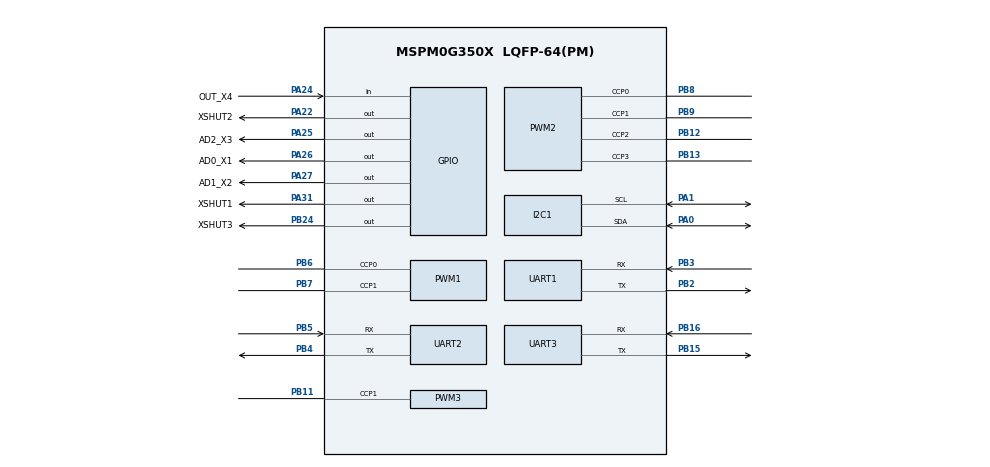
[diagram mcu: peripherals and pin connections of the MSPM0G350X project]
/**
 * @cliArgs --device "MSPM0G350X" --part "Default" --package "LQFP-64(PM)" --product "mspm0_sdk@2.02.00.05"
 * @versions {"tool":"1.21.1+3772"}
 */

/**
 * Import the modules used in this configuration.
 */
const ADC12   = scripting.addModule("/ti/driverlib/ADC12", {}, false);
const ADC121  = ADC12.addInstance();
const GPIO    = scripting.addModule("/ti/driverlib/GPIO", {}, false);
const GPIO1   = GPIO.addInstance();
const GPIO2   = GPIO.addInstance();
const GPIO3   = GPIO.addInstance();
const GPIO4   = GPIO.addInstance();
const GPIO5   = GPIO.addInstance();
const I2C     = scripting.addModule("/ti/driverlib/I2C", {}, false);
const I2C1    = I2C.addInstance();
const PWM     = scripting.addModule("/ti/driverlib/PWM", {}, false);
const PWM1    = PWM.addInstance();
const PWM2    = PWM.addInstance();
const PWM3    = PWM.addInstance();
const SYSCTL  = scripting.addModule("/ti/driverlib/SYSCTL");
const SYSTICK = scripting.addModule("/ti/driverlib/SYSTICK");
const TIMER   = scripting.addModule("/ti/driverlib/TIMER", {}, false);
const TIMER1  = TIMER.addInstance();
const UART    = scripting.addModule("/ti/driverlib/UART", {}, false);
const UART1   = UART.addInstance();
const UART2   = UART.addInstance();
const UART3   = UART.addInstance();
const UART4   = UART.addInstance();

/**
 * Write custom configuration values to the imported modules.
 */
const divider6       = system.clockTree["PLL_CLK2X_DIV"];
divider6.divideValue = 4;

const divider7       = system.clockTree["PLL_PDIV"];
divider7.divideValue = 2;

const divider9       = system.clockTree["UDIV"];
divider9.divideValue = 2;

const gate7  = system.clockTree["MFCLKGATE"];
gate7.enable = true;

const multiplier2         = system.clockTree["PLL_QDIV"];
multiplier2.multiplyValue = 10;

const mux8       = system.clockTree["HSCLKMUX"];
mux8.inputSelect = "HSCLKMUX_SYSPLL2X";

ADC121.$name                             = "ADC_BAT";
ADC121.enabledInterrupts                 = ["DL_ADC12_INTERRUPT_MEM0_RESULT_LOADED"];
ADC121.adcMem0trig                       = "DL_ADC12_TRIGGER_MODE_TRIGGER_NEXT";
ADC121.sampClkSrc                        = "DL_ADC12_CLOCK_ULPCLK";
ADC121.sampClkDiv                        = "DL_ADC12_CLOCK_DIVIDE_8";
ADC121.powerDownMode                     = "DL_ADC12_POWER_DOWN_MODE_MANUAL";
ADC121.sampleTime1                       = "0.25ms";
ADC121.sampleTime0                       = "0.25ms";
ADC121.peripheral.$assign                = "ADC1";
ADC121.peripheral.adcPin0.$assign        = "PA15";
ADC121.adcPin0Config.hideOutputInversion = scripting.forceWrite(false);
ADC121.adcPin0Config.$name               = "ti_driverlib_gpio_GPIOPinGeneric14";

const Board = scripting.addModule("/ti/driverlib/Board", {}, false);

GPIO1.$name                         = "XSHUT";
GPIO1.associatedPins.create(3);
GPIO1.associatedPins[0].$name       = "XSHUT1";
GPIO1.associatedPins[0].pin.$assign = "PA31";
GPIO1.associatedPins[1].$name       = "XSHUT2";
GPIO1.associatedPins[1].pin.$assign = "PA22";
GPIO1.associatedPins[2].$name       = "XSHUT3";
GPIO1.associatedPins[2].pin.$assign = "PB24";

GPIO2.$name                         = "LINE_FOLLOW";
GPIO2.associatedPins.create(4);
GPIO2.associatedPins[0].$name       = "AD0_X1";
GPIO2.associatedPins[0].pin.$assign = "PA26";
GPIO2.associatedPins[1].$name       = "AD1_X2";
GPIO2.associatedPins[1].pin.$assign = "PA27";
GPIO2.associatedPins[2].$name       = "AD2_X3";
GPIO2.associatedPins[2].pin.$assign = "PA25";
GPIO2.associatedPins[3].$name       = "OUT_X4";
GPIO2.associatedPins[3].direction   = "INPUT";
GPIO2.associatedPins[3].pin.$assign = "PA24";

GPIO3.$name                              = "KEY";
GPIO3.associatedPins.create(4);
GPIO3.associatedPins[0].$name            = "KEY2";
GPIO3.associatedPins[0].direction        = "INPUT";
GPIO3.associatedPins[0].assignedPort     = "PORTA";
GPIO3.associatedPins[0].assignedPin      = "8";
GPIO3.associatedPins[0].internalResistor = "PULL_UP";
GPIO3.associatedPins[1].$name            = "KEY1";
GPIO3.associatedPins[1].direction        = "INPUT";
GPIO3.associatedPins[1].assignedPort     = "PORTA";
GPIO3.associatedPins[1].assignedPin      = "28";
GPIO3.associatedPins[1].internalResistor = "PULL_UP";
GPIO3.associatedPins[2].$name            = "KEY3";
GPIO3.associatedPins[2].direction        = "INPUT";
GPIO3.associatedPins[2].assignedPort     = "PORTA";
GPIO3.associatedPins[2].assignedPin      = "9";
GPIO3.associatedPins[2].internalResistor = "PULL_UP";
GPIO3.associatedPins[3].$name            = "STOP";
GPIO3.associatedPins[3].direction        = "INPUT";
GPIO3.associatedPins[3].assignedPort     = "PORTB";
GPIO3.associatedPins[3].internalResistor = "PULL_UP";
GPIO3.associatedPins[3].assignedPin      = "1";

GPIO4.$name                          = "LED";
GPIO4.associatedPins.create(3);
GPIO4.associatedPins[0].$name        = "LED_0";
GPIO4.associatedPins[0].assignedPort = "PORTA";
GPIO4.associatedPins[0].assignedPin  = "30";
GPIO4.associatedPins[1].$name        = "LED_1";
GPIO4.associatedPins[1].assignedPort = "PORTB";
GPIO4.associatedPins[1].assignedPin  = "0";
GPIO4.associatedPins[2].$name        = "LED_2";
GPIO4.associatedPins[2].assignedPort = "PORTB";
GPIO4.associatedPins[2].assignedPin  = "22";

GPIO5.$name                                 = "ENCODER";
GPIO5.associatedPins.create(4);
GPIO5.associatedPins[0].$name               = "E1A";
GPIO5.associatedPins[0].direction           = "INPUT";
GPIO5.associatedPins[0].interruptEn         = true;
GPIO5.associatedPins[0].polarity            = "RISE_FALL";
GPIO5.associatedPins[0].assignedPort        = "PORTA";
GPIO5.associatedPins[0].assignedPin         = "12";
GPIO5.associatedPins[0].inputFilter         = "3_CYCLES";
GPIO5.associatedPins[1].$name               = "E1B";
GPIO5.associatedPins[1].direction           = "INPUT";
GPIO5.associatedPins[1].assignedPort        = "PORTA";
GPIO5.associatedPins[1].assignedPin         = "13";
GPIO5.associatedPins[1].interruptEn         = true;
GPIO5.associatedPins[1].polarity            = "RISE";
GPIO5.associatedPins[1].inputFilter         = "3_CYCLES";
GPIO5.associatedPins[2].$name               = "E2A";
GPIO5.associatedPins[2].direction           = "INPUT";
GPIO5.associatedPins[2].assignedPort        = "PORTB";
GPIO5.associatedPins[2].assignedPin         = "23";
GPIO5.associatedPins[2].interruptEn         = true;
GPIO5.associatedPins[2].polarity            = "RISE_FALL";
GPIO5.associatedPins[2].inputFilter         = "8_CYCLES";
GPIO5.associatedPins[3].$name               = "E2B";
GPIO5.associatedPins[3].direction           = "INPUT";
GPIO5.associatedPins[3].assignedPin         = "27";
GPIO5.associatedPins[3].interruptEn         = true;
GPIO5.associatedPins[3].polarity            = "RISE";
GPIO5.associatedPins[3].assignedPort        = "PORTB";
GPIO5.associatedPins[3].assignedPortSegment = "Upper";
GPIO5.associatedPins[3].inputFilter         = "8_CYCLES";

I2C1.$name                             = "I2C_VL53L0X";
I2C1.basicEnableController             = true;
I2C1.advDigitalGlitchFilter            = "CLOCKS_1";
I2C1.enableDMAEvent1                   = false;
I2C1.enableDMAEvent2                   = false;
I2C1.basicTargetSecAddressEnable       = true;
I2C1.peripheral.$assign                = "I2C0";
I2C1.peripheral.sdaPin.$assign         = "PA0";
I2C1.peripheral.sclPin.$assign         = "PA1";
I2C1.sdaPinConfig.hideOutputInversion  = scripting.forceWrite(false);
I2C1.sdaPinConfig.onlyInternalResistor = scripting.forceWrite(false);
I2C1.sdaPinConfig.passedPeripheralType = scripting.forceWrite("Digital");
I2C1.sdaPinConfig.$name                = "ti_driverlib_gpio_GPIOPinGeneric8";
I2C1.sdaPinConfig.enableConfig         = true;
I2C1.sclPinConfig.hideOutputInversion  = scripting.forceWrite(false);
I2C1.sclPinConfig.onlyInternalResistor = scripting.forceWrite(false);
I2C1.sclPinConfig.passedPeripheralType = scripting.forceWrite("Digital");
I2C1.sclPinConfig.$name                = "ti_driverlib_gpio_GPIOPinGeneric9";
I2C1.sclPinConfig.enableConfig         = true;

PWM1.clockPrescale                      = 160;
PWM1.timerCount                         = 10000;
PWM1.$name                              = "SERVO";
PWM1.pwmMode                            = "EDGE_ALIGN_UP";
PWM1.peripheral.$assign                 = "TIMG6";
PWM1.peripheral.ccp0Pin.$assign         = "PB6";
PWM1.peripheral.ccp1Pin.$assign         = "PB7";
PWM1.PWM_CHANNEL_0.$name                = "ti_driverlib_pwm_PWMTimerCC2";
PWM1.PWM_CHANNEL_1.$name                = "ti_driverlib_pwm_PWMTimerCC3";
PWM1.ccp0PinConfig.direction            = scripting.forceWrite("OUTPUT");
PWM1.ccp0PinConfig.hideOutputInversion  = scripting.forceWrite(false);
PWM1.ccp0PinConfig.onlyInternalResistor = scripting.forceWrite(false);
PWM1.ccp0PinConfig.passedPeripheralType = scripting.forceWrite("Digital");
PWM1.ccp0PinConfig.$name                = "ti_driverlib_gpio_GPIOPinGeneric12";
PWM1.ccp1PinConfig.direction            = scripting.forceWrite("OUTPUT");
PWM1.ccp1PinConfig.hideOutputInversion  = scripting.forceWrite(false);
PWM1.ccp1PinConfig.onlyInternalResistor = scripting.forceWrite(false);
PWM1.ccp1PinConfig.passedPeripheralType = scripting.forceWrite("Digital");
PWM1.ccp1PinConfig.$name                = "ti_driverlib_gpio_GPIOPinGeneric13";

PWM2.$name                              = "MOTOR";
PWM2.ccIndex                            = [0,1,2,3];
PWM2.timerCount                         = 8000;
PWM2.pwmMode                            = "EDGE_ALIGN_UP";
PWM2.peripheral.$assign                 = "TIMA0";
PWM2.peripheral.ccp0Pin.$assign         = "PB8";
PWM2.peripheral.ccp1Pin.$assign         = "PB9";
PWM2.peripheral.ccp2Pin.$assign         = "PB12";
PWM2.peripheral.ccp3Pin.$assign         = "PB13";
PWM2.PWM_CHANNEL_0.$name                = "ti_driverlib_pwm_PWMTimerCC0";
PWM2.PWM_CHANNEL_1.$name                = "ti_driverlib_pwm_PWMTimerCC1";
PWM2.ccp0PinConfig.direction            = scripting.forceWrite("OUTPUT");
PWM2.ccp0PinConfig.hideOutputInversion  = scripting.forceWrite(false);
PWM2.ccp0PinConfig.onlyInternalResistor = scripting.forceWrite(false);
PWM2.ccp0PinConfig.passedPeripheralType = scripting.forceWrite("Digital");
PWM2.ccp0PinConfig.$name                = "ti_driverlib_gpio_GPIOPinGeneric10";
PWM2.ccp1PinConfig.direction            = scripting.forceWrite("OUTPUT");
PWM2.ccp1PinConfig.hideOutputInversion  = scripting.forceWrite(false);
PWM2.ccp1PinConfig.onlyInternalResistor = scripting.forceWrite(false);
PWM2.ccp1PinConfig.passedPeripheralType = scripting.forceWrite("Digital");
PWM2.ccp1PinConfig.$name                = "ti_driverlib_gpio_GPIOPinGeneric11";
PWM2.PWM_CHANNEL_2.$name                = "ti_driverlib_pwm_PWMTimerCC4";
PWM2.PWM_CHANNEL_3.$name                = "ti_driverlib_pwm_PWMTimerCC5";
PWM2.ccp2PinConfig.$name                = "ti_driverlib_gpio_GPIOPinGeneric15";
PWM2.ccp3PinConfig.$name                = "ti_driverlib_gpio_GPIOPinGeneric16";

PWM3.timerCount                         = 10000;
PWM3.clockPrescale                      = 80;
PWM3.$name                              = "SERVO3";
PWM3.ccIndex                            = [1];
PWM3.pwmMode                            = "EDGE_ALIGN_UP";
PWM3.peripheral.ccp1Pin.$assign         = "PB11";
PWM3.ccp1PinConfig.$name                = "ti_driverlib_gpio_GPIOPinGeneric18";
PWM3.ccp1PinConfig.direction            = scripting.forceWrite("OUTPUT");
PWM3.ccp1PinConfig.hideOutputInversion  = scripting.forceWrite(false);
PWM3.ccp1PinConfig.onlyInternalResistor = scripting.forceWrite(false);
PWM3.ccp1PinConfig.passedPeripheralType = scripting.forceWrite("Digital");
PWM3.PWM_CHANNEL_1.$name                = "ti_driverlib_pwm_PWMTimerCC6";

SYSCTL.forceDefaultClkConfig = true;
SYSCTL.clockTreeEn           = true;

SYSTICK.periodEnable      = true;
SYSTICK.interruptEnable   = true;
SYSTICK.systickEnable     = true;
SYSTICK.period            = 80000;
SYSTICK.interruptPriority = "0";

TIMER1.$name              = "TIMER_0";
TIMER1.timerClkSrc        = "MFCLK";
TIMER1.interruptPriority  = "2";
TIMER1.timerPeriod        = "1ms";
TIMER1.interrupts         = ["ZERO"];
TIMER1.timerMode          = "PERIODIC";
TIMER1.peripheral.$assign = "TIMA1";

UART1.$name                            = "MSPMotor";
UART1.targetBaudRate                   = 115200;
UART1.uartClkSrc                       = "MFCLK";
UART1.interruptPriority                = "1";
UART1.enabledInterrupts                = ["RX"];
UART1.peripheral.$assign               = "UART3";
UART1.peripheral.rxPin.$assign         = "PB3";
UART1.peripheral.txPin.$assign         = "PB2";
UART1.txPinConfig.direction            = scripting.forceWrite("OUTPUT");
UART1.txPinConfig.hideOutputInversion  = scripting.forceWrite(false);
UART1.txPinConfig.onlyInternalResistor = scripting.forceWrite(false);
UART1.txPinConfig.passedPeripheralType = scripting.forceWrite("Digital");
UART1.txPinConfig.$name                = "ti_driverlib_gpio_GPIOPinGeneric2";
UART1.rxPinConfig.hideOutputInversion  = scripting.forceWrite(false);
UART1.rxPinConfig.onlyInternalResistor = scripting.forceWrite(false);
UART1.rxPinConfig.passedPeripheralType = scripting.forceWrite("Digital");
UART1.rxPinConfig.$name                = "ti_driverlib_gpio_GPIOPinGeneric3";

UART2.$name                            = "IMU";
UART2.enabledInterrupts                = ["RX"];
UART2.targetBaudRate                   = 115200;
UART2.interruptPriority                = "1";
UART2.peripheral.rxPin.$assign         = "PB5";
UART2.peripheral.txPin.$assign         = "PB4";
UART2.txPinConfig.direction            = scripting.forceWrite("OUTPUT");
UART2.txPinConfig.hideOutputInversion  = scripting.forceWrite(false);
UART2.txPinConfig.onlyInternalResistor = scripting.forceWrite(false);
UART2.txPinConfig.passedPeripheralType = scripting.forceWrite("Digital");
UART2.txPinConfig.$name                = "ti_driverlib_gpio_GPIOPinGeneric4";
UART2.rxPinConfig.hideOutputInversion  = scripting.forceWrite(false);
UART2.rxPinConfig.onlyInternalResistor = scripting.forceWrite(false);
UART2.rxPinConfig.passedPeripheralType = scripting.forceWrite("Digital");
UART2.rxPinConfig.$name                = "ti_driverlib_gpio_GPIOPinGeneric5";

UART3.$name                            = "Vision";
UART3.targetBaudRate                   = 115200;
UART3.peripheral.rxPin.$assign         = "PB16";
UART3.peripheral.txPin.$assign         = "PB15";
UART3.txPinConfig.direction            = scripting.forceWrite("OUTPUT");
UART3.txPinConfig.hideOutputInversion  = scripting.forceWrite(false);
UART3.txPinConfig.onlyInternalResistor = scripting.forceWrite(false);
UART3.txPinConfig.passedPeripheralType = scripting.forceWrite("Digital");
UART3.txPinConfig.$name                = "ti_driverlib_gpio_GPIOPinGeneric6";
UART3.rxPinConfig.hideOutputInversion  = scripting.forceWrite(false);
UART3.rxPinConfig.onlyInternalResistor = scripting.forceWrite(false);
UART3.rxPinConfig.passedPeripheralType = scripting.forceWrite("Digital");
UART3.rxPinConfig.$name                = "ti_driverlib_gpio_GPIOPinGeneric7";

UART4.$name                            = "user";
UART4.uartClkSrc                       = "MFCLK";
UART4.targetBaudRate                   = 115200;
UART4.txPinConfig.direction            = scripting.forceWrite("OUTPUT");
UART4.txPinConfig.hideOutputInversion  = scripting.forceWrite(false);
UART4.txPinConfig.onlyInternalResistor = scripting.forceWrite(false);
UART4.txPinConfig.passedPeripheralType = scripting.forceWrite("Digital");
UART4.txPinConfig.$name                = "ti_driverlib_gpio_GPIOPinGeneric0";
UART4.rxPinConfig.hideOutputInversion  = scripting.forceWrite(false);
UART4.rxPinConfig.onlyInternalResistor = scripting.forceWrite(false);
UART4.rxPinConfig.passedPeripheralType = scripting.forceWrite("Digital");
UART4.rxPinConfig.$name                = "ti_driverlib_gpio_GPIOPinGeneric1";

/**
 * Pinmux solution for unlocked pins/peripherals. This ensures that minor changes to the automatic solver in a future
 * version of the tool will not impact the pinmux you originally saw.  These lines can be completely deleted in order to
 * re-solve from scratch.
 */
Board.peripheral.$suggestSolution            = "DEBUGSS";
Board.peripheral.swclkPin.$suggestSolution   = "PA20";
Board.peripheral.swdioPin.$suggestSolution   = "PA19";
GPIO3.associatedPins[0].pin.$suggestSolution = "PA8";
GPIO3.associatedPins[1].pin.$suggestSolution = "PA28";
GPIO3.associatedPins[2].pin.$suggestSolution = "PA9";
GPIO3.associatedPins[3].pin.$suggestSolution = "PB1";
GPIO4.associatedPins[0].pin.$suggestSolution = "PA30";
GPIO4.associatedPins[1].pin.$suggestSolution = "PB0";
GPIO4.associatedPins[2].pin.$suggestSolution = "PB22";
GPIO5.associatedPins[0].pin.$suggestSolution = "PA12";
GPIO5.associatedPins[1].pin.$suggestSolution = "PA13";
GPIO5.associatedPins[2].pin.$suggestSolution = "PB23";
GPIO5.associatedPins[3].pin.$suggestSolution = "PB27";
PWM3.peripheral.$suggestSolution             = "TIMG0";
UART2.peripheral.$suggestSolution            = "UART1";
UART3.peripheral.$suggestSolution            = "UART2";
UART4.peripheral.$suggestSolution            = "UART0";
UART4.peripheral.rxPin.$suggestSolution      = "PA11";
UART4.peripheral.txPin.$suggestSolution      = "PA10";
